# RL7005_IP_SVD register map
Vendor: Realtek
Registers are 32-bit, read-write, reset 0x0 unless marked. A register's access mark holds for its fields unless they carry their own. Offsets are from the block's base; [hi:lo] are bit positions; <NAME> marks a mode.

## PKE_REG
Base 0x400C0000
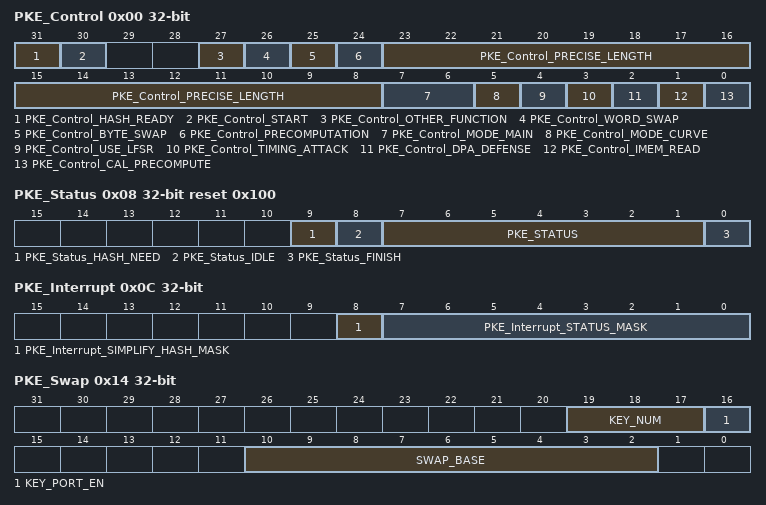
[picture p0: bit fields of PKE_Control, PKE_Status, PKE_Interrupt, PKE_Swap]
0x00 PKE_Control
  [31] PKE_Control_HASH_READY — Write 1 to inform PKE that hash value used in SIMPLIFY ECDSA/EDDSA are ready
  [30] PKE_Control_START — Write 1 to start PKE (cleared automatically by PKE)
  [27] PKE_Control_OTHER_FUNCTION — Other functions (not RSA/ECC) enable bit 1: enabled 0: disabled (RSA: modular exponentiation; ECC: scalar multiplication)
  [26] PKE_Control_WORD_SWAP — Endian word swap enable (only supported in MMEM)
  [25] PKE_Control_BYTE_SWAP — Endian byte swap enable (only supported in MMEM)
  [24] PKE_Control_PRECOMPUTATION — R^2 mod N ready (1 means not need to calculate the R^2 mod N, already stored by user) For RSA , R^2 mod N ready and DPA defense can't be enabled at the same time. Valid only when bit[27] == 0
  [23:8] PKE_Control_PRECISE_LENGTH — Precise RSA/ECC length in bits Caution: when preforming ecc point operation under binary field, there are situation which width of modulo is larger than ecc length. For example, width of f(x) of sect163r2 is 164, larger than ECC length 163. In this situation, just fill in Precise ECC length 163.
  [7:6] PKE_Control_MODE_MAIN — 2'b00: ECC Prime field 2'b01: ECC Binary field 2'b10: RSA 2'b11: Edwards or Montgomery Curves
  [5] PKE_Control_MODE_CURVE — 1'b0: Edward Curves 1'b1: Montgomery Curves
  [4] PKE_Control_USE_LFSR — 1: use internal LFSR0, and do not use internal LFSR. If user does not use internal LFSR, user needs to initial a 32-bit random number (can't be 0) to MMEM offset 0x600 (RSA3072), or MMEM offser 0x800 (RSA4096) or MMEM offset 0x380 (ECC). And if configured to ECC, please also clear the upper MMEM offset 0x381 to 0x3bf to 0.
  [3] PKE_Control_TIMING_ATTACK — 1: Timing attack defense enable 0: Timing attack defense disable
  [2] PKE_Control_DPA_DEFENSE — 1: DPA defense enable 0: DPA defense disable
  [1] PKE_Control_IMEM_READ — 1: Enable IMEM read (or else, the IMEM can only be read when bit[30] = 1) 0: IMEM can't be read
  [0] PKE_Control_CAL_PRECOMPUTE — When using RSA/ECC (bit 27 == 0), if this bit is set, PKE will calculate R ^ 2 mod N, n[63:0] ^ (-1) mod r only
0x08 PKE_Status access per field reset 0x100
  [9] PKE_Status_HASH_NEED ro — SIMPLIFY_ECDSA/EdDSA needs hash value
  [8] PKE_Status_IDLE ro — PKE idle
  [7:1] PKE_STATUS rw — 7'h1: prime check error(for modular number) 7'h2: R^2 mod N failed 7'h4: ECC odd point (Y = 0) (Montgomery curve will not check the Y value) 7'h5: RSA not supported 7'h6: check version error 7'h7: no such function 7'h8: ECC Z = 0 7'h10: Modular Inverse failed 7'h20: N < input message for RSA 7'h40: No valid exponent
  [0] PKE_Status_FINISH rw — PKE operation finish
0x0C PKE_Interrupt — PKE Interrupt Mask Register
  [8] PKE_Interrupt_SIMPLIFY_HASH_MASK — Wait for SIMPLIFY_ECDSA_EDDSA hash value 0: interrupt masked 1: interrupt not masked
  [7:0] PKE_Interrupt_STATUS_MASK — Interrupt mask for interrupt in PKE status register bit[7:0] 8'h00: interrupt masked 8'hff: interrupt not masked Caution: valid value of this field is only 8'h00 or 8'hff
0x14 PKE_Swap — Base addess of word swap Register
  [19:17] KEY_NUM — Use which key (binary encoding), key0 ~ key7
  [16] KEY_PORT_EN — 1: Enable hardware key port 0: Do not enable hardware key port
  [10:2] SWAP_BASE — Word swap base address in word (32 bits)
0x1C PKE_Version ro — Version Number Register
  [31:0] VERSION — 32-bit code update date or version number , such as 32'h20211015
0x2C LFSR_Seed wo — PKESeeding Register
  [31:0] SEED — Seed of internal LFSRs
0x34 PKE_MUTEX
  [1:0] MUTEX_STATUS — If read 0, lock mutex. If not 0, the engine is being used. 2'b01: secure domain lock mutex 2'b10: non-secure domain lock mutex Write 0 to unlock mutex
0x38 PKE_MUTEX_OVERWRITE
  [0] MUTEX_OVERWRITE — Allows secure domain overwrite mutex 1: Enable 0: Disable
